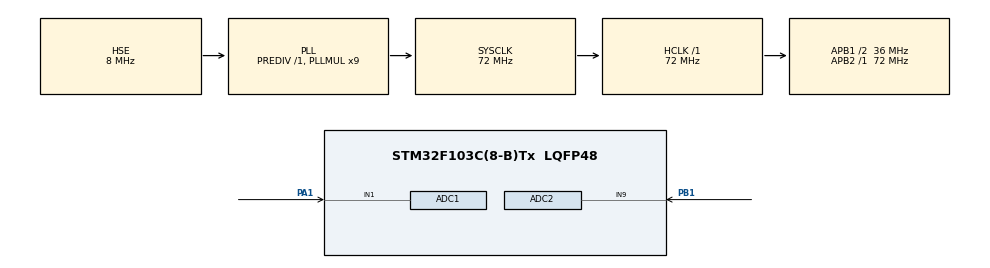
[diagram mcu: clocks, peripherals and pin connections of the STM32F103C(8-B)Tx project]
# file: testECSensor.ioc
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ADC1.Channel-2\#ChannelRegularConversion=ADC_CHANNEL_1
ADC1.ContinuousConvMode=DISABLE
ADC1.NbrOfConversion=1
ADC1.NbrOfConversionFlag=1
ADC1.Rank-2\#ChannelRegularConversion=1
ADC1.SamplingTime-2\#ChannelRegularConversion=ADC_SAMPLETIME_1CYCLE_5
ADC1.master=1
ADC2.Channel-1\#ChannelRegularConversion=ADC_CHANNEL_9
ADC2.ContinuousConvMode=DISABLE
ADC2.NbrOfConversionFlag=1
ADC2.Rank-1\#ChannelRegularConversion=1
ADC2.SamplingTime-1\#ChannelRegularConversion=ADC_SAMPLETIME_1CYCLE_5
Mcu.Family=STM32F1
Mcu.Name=STM32F103C(8-B)Tx
Mcu.Package=LQFP48
NVIC.PriorityGroup=NVIC_PRIORITYGROUP_4
PA1.Signal=ADCx_IN1
PA13.Mode=Serial_Wire
PA13.Signal=SYS_JTMS-SWDIO
PA14.Mode=Serial_Wire
PA14.Signal=SYS_JTCK-SWCLK
PB1.Signal=ADCx_IN9
PD0-OSC_IN.Mode=HSE-External-Oscillator
PD0-OSC_IN.Signal=RCC_OSC_IN
PD1-OSC_OUT.Mode=HSE-External-Oscillator
PD1-OSC_OUT.Signal=RCC_OSC_OUT
ProjectManager.HeapSize=0x200
ProjectManager.StackSize=0x400
ProjectManager.TargetToolchain=MDK-ARM V5.32
RCC.ADCPresc=RCC_ADCPCLK2_DIV6
RCC.AHBFreq_Value=72000000
RCC.APB1CLKDivider=RCC_HCLK_DIV2
RCC.APB1Freq_Value=36000000
RCC.APB1TimFreq_Value=72000000
RCC.APB2Freq_Value=72000000
RCC.APB2TimFreq_Value=72000000
RCC.HCLKFreq_Value=72000000
RCC.PLLMUL=RCC_PLL_MUL9
RCC.PLLSourceVirtual=RCC_PLLSOURCE_HSE
RCC.SYSCLKFreq_VALUE=72000000
RCC.SYSCLKSource=RCC_SYSCLKSOURCE_PLLCLK
RCC.USBFreq_Value=72000000
SH.ADCx_IN1.0=ADC1_IN1,IN1
SH.ADCx_IN9.0=ADC2_IN9,IN9
board=custom

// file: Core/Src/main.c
/* USER CODE BEGIN Header */
/**
  ******************************************************************************
  * @file           : main.c
  * @brief          : Main program body
  ******************************************************************************
  * @attention
  *
  * Copyright (c) 2024 STMicroelectronics.
  * All rights reserved.
  *
  * This software is licensed under terms that can be found in the LICENSE file
  * in the root directory of this software component.
  * If no LICENSE file comes with this software, it is provided AS-IS.
  *
  ******************************************************************************
  */
/* USER CODE END Header */
#include "main.h"

/* USER CODE BEGIN Includes */
#include <stdbool.h>
/* USER CODE END Includes */

ADC_HandleTypeDef hadc1;
ADC_HandleTypeDef hadc2;

void SystemClock_Config(void);
static void MX_GPIO_Init(void);
static void MX_ADC1_Init(void);
static void MX_ADC2_Init(void);

/* USER CODE BEGIN 0 */
float kvalue = 1;
float adcValue = 0;
float adcValue2 = 0;
float ec = 0;
float te = 0;
float value = 0;
float temp = 0;
float conductivity = 0;
#define RES2 820.0
#define ECREF 200.0
#define GDIFF (30/1.8)
#define VR0  0.223
#define G0  2
#define I  (1.24 / 10000)

float volCal(float input){
  return input;
}

float calibrate(float voltage)
{
  voltage = volCal(voltage);
  float KValueTemp = RES2*ECREF*1413/100000.0/voltage;
  return KValueTemp;
}

bool setCalibration(float calibration)
{
  if((calibration>=0.5)&&(calibration<=1.5))
  {
    kvalue = calibration;
    return 1;
  }else
    return 0;
}

float convVoltagetoTemperature_C(float voltage)
{
  voltage = volCal(voltage);
  float Rpt1000 = (voltage/GDIFF+VR0)/I/G0;
  float temp = (Rpt1000-1000)/3.85;
  return temp;
}

float getEC_us_cm(float voltage, float temperature)
{
  voltage = volCal(voltage);
  float ecvalueRaw = 100000 * voltage / RES2 / ECREF * kvalue;
  float value = ecvalueRaw / (1.0 + 0.02 * (temperature - 25.0));
  return value;
}
/* USER CODE END 0 */

int main(void)
{

  /* MCU Configuration--------------------------------------------------------*/

  /* Reset of all peripherals, Initializes the Flash interface and the Systick. */
  HAL_Init();

  /* Configure the system clock */
  SystemClock_Config();

  /* Initialize all configured peripherals */
  MX_GPIO_Init();
  MX_ADC1_Init();
  MX_ADC2_Init();
  /* USER CODE BEGIN 2 */
	setCalibration(calibrate(14131413.00));
  /* USER CODE END 2 */

  /* Infinite loop */
  while (1)
  {

    /* USER CODE BEGIN 3 */
		HAL_ADC_Start(&hadc2);
		HAL_Delay(1);
		adcValue = HAL_ADC_GetValue(&hadc2)*3300/4095;
		HAL_ADC_Stop(&hadc2);
		te = 783;
		HAL_ADC_Start(&hadc1);
		HAL_Delay(1);
		adcValue2 = HAL_ADC_GetValue(&hadc1)*3300/4095;
		HAL_ADC_Stop(&hadc1);

		temp = convVoltagetoTemperature_C((float)adcValue2/ 1000);;
		conductivity = getEC_us_cm(adcValue, temp);

  }
  /* USER CODE END 3 */
}

void SystemClock_Config(void)
{
  RCC_OscInitTypeDef RCC_OscInitStruct = {0};
  RCC_ClkInitTypeDef RCC_ClkInitStruct = {0};
  RCC_PeriphCLKInitTypeDef PeriphClkInit = {0};

  /** Initializes the RCC Oscillators according to the specified parameters
  * in the RCC_OscInitTypeDef structure.
  */
  RCC_OscInitStruct.OscillatorType = RCC_OSCILLATORTYPE_HSE;
  RCC_OscInitStruct.HSEState = RCC_HSE_ON;
  RCC_OscInitStruct.HSEPredivValue = RCC_HSE_PREDIV_DIV1;
  RCC_OscInitStruct.HSIState = RCC_HSI_ON;
  RCC_OscInitStruct.PLL.PLLState = RCC_PLL_ON;
  RCC_OscInitStruct.PLL.PLLSource = RCC_PLLSOURCE_HSE;
  RCC_OscInitStruct.PLL.PLLMUL = RCC_PLL_MUL9;
  if (HAL_RCC_OscConfig(&RCC_OscInitStruct) != HAL_OK)
  {
    Error_Handler();
  }

  /** Initializes the CPU, AHB and APB buses clocks
  */
  RCC_ClkInitStruct.ClockType = RCC_CLOCKTYPE_HCLK|RCC_CLOCKTYPE_SYSCLK
                              |RCC_CLOCKTYPE_PCLK1|RCC_CLOCKTYPE_PCLK2;
  RCC_ClkInitStruct.SYSCLKSource = RCC_SYSCLKSOURCE_PLLCLK;
  RCC_ClkInitStruct.AHBCLKDivider = RCC_SYSCLK_DIV1;
  RCC_ClkInitStruct.APB1CLKDivider = RCC_HCLK_DIV2;
  RCC_ClkInitStruct.APB2CLKDivider = RCC_HCLK_DIV1;

  if (HAL_RCC_ClockConfig(&RCC_ClkInitStruct, FLASH_LATENCY_2) != HAL_OK)
  {
    Error_Handler();
  }
  PeriphClkInit.PeriphClockSelection = RCC_PERIPHCLK_ADC;
  PeriphClkInit.AdcClockSelection = RCC_ADCPCLK2_DIV6;
  if (HAL_RCCEx_PeriphCLKConfig(&PeriphClkInit) != HAL_OK)
  {
    Error_Handler();
  }
}

static void MX_ADC1_Init(void)
{

  ADC_ChannelConfTypeDef sConfig = {0};

  /** Common config
  */
  hadc1.Instance = ADC1;
  hadc1.Init.ScanConvMode = ADC_SCAN_DISABLE;
  hadc1.Init.ContinuousConvMode = DISABLE;
  hadc1.Init.DiscontinuousConvMode = DISABLE;
  hadc1.Init.ExternalTrigConv = ADC_SOFTWARE_START;
  hadc1.Init.DataAlign = ADC_DATAALIGN_RIGHT;
  hadc1.Init.NbrOfConversion = 1;
  if (HAL_ADC_Init(&hadc1) != HAL_OK)
  {
    Error_Handler();
  }

  /** Configure Regular Channel
  */
  sConfig.Channel = ADC_CHANNEL_1;
  sConfig.Rank = ADC_REGULAR_RANK_1;
  sConfig.SamplingTime = ADC_SAMPLETIME_1CYCLE_5;
  if (HAL_ADC_ConfigChannel(&hadc1, &sConfig) != HAL_OK)
  {
    Error_Handler();
  }

}

static void MX_ADC2_Init(void)
{

  ADC_ChannelConfTypeDef sConfig = {0};

  /** Common config
  */
  hadc2.Instance = ADC2;
  hadc2.Init.ScanConvMode = ADC_SCAN_DISABLE;
  hadc2.Init.ContinuousConvMode = DISABLE;
  hadc2.Init.DiscontinuousConvMode = DISABLE;
  hadc2.Init.ExternalTrigConv = ADC_SOFTWARE_START;
  hadc2.Init.DataAlign = ADC_DATAALIGN_RIGHT;
  hadc2.Init.NbrOfConversion = 1;
  if (HAL_ADC_Init(&hadc2) != HAL_OK)
  {
    Error_Handler();
  }

  /** Configure Regular Channel
  */
  sConfig.Channel = ADC_CHANNEL_9;
  sConfig.Rank = ADC_REGULAR_RANK_1;
  sConfig.SamplingTime = ADC_SAMPLETIME_1CYCLE_5;
  if (HAL_ADC_ConfigChannel(&hadc2, &sConfig) != HAL_OK)
  {
    Error_Handler();
  }

}

static void MX_GPIO_Init(void)
{

  /* GPIO Ports Clock Enable */
  __HAL_RCC_GPIOD_CLK_ENABLE();
  __HAL_RCC_GPIOA_CLK_ENABLE();
  __HAL_RCC_GPIOB_CLK_ENABLE();

}

void Error_Handler(void)
{
  __disable_irq();
  while (1)
  {
  }
}
